# COMPUTE_CLUSTER_ARM_COREPACK_0_COMPUTE_CLUSTER_ARM_COREPACK_0_APBADDR_DBG_CPU0_000730010000h register map
Vendor: Texas Instruments
Registers are 32-bit, read-write, reset 0x0 unless marked. A register's access mark holds for its fields unless they carry their own. Offsets are as the file gives them; [hi:lo] are bit positions; {n}, {i} and the like mark numbered series.

## COMPUTE_CLUSTER_ARM_COREPACK_0_APBADDR_DBG_CPU0 (part 2 of 2)
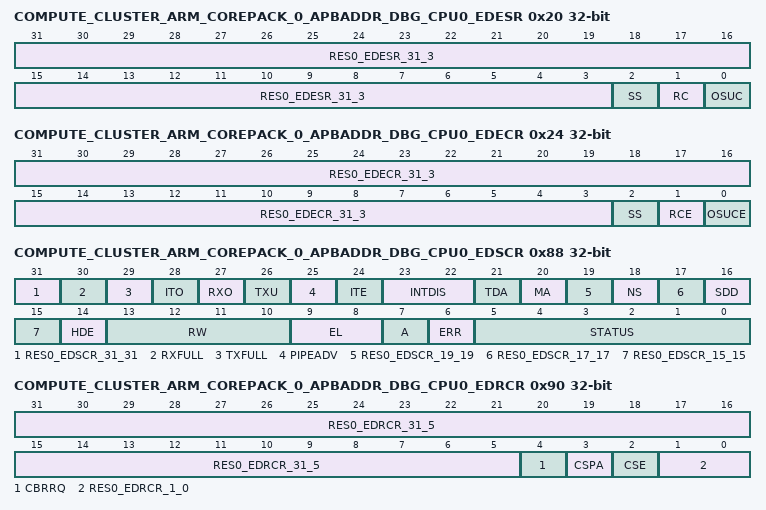
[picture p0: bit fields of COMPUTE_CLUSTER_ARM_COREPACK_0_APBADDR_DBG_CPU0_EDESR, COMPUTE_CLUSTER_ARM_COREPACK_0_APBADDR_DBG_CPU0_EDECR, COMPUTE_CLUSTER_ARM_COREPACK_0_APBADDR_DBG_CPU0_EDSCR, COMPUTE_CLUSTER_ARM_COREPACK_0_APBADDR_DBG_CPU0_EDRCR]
0x20 COMPUTE_CLUSTER_ARM_COREPACK_0_APBADDR_DBG_CPU0_EDESR — External Debug Event Status Register
  [31:3] RES0_EDESR_31_3 — Reserved, RES0.
  [2] SS — Halting step debug event pending. Possible values of this field are: 0 Reading this means that a Halting step debug event is not pending. Writing this means no action. 1 Reading this means that a Halting step debug event is pending. Writing this clears the pending Halting step debug event.
  [1] RC — Reset catch debug event pending. Possible values of this field are: 0 Reading this means that a Reset catch debug event is not pending. Writing this means no action. 1 Reading this means that a Reset catch debug event is pending. Writing this clears the pending Reset catch debug event.
  [0] OSUC — OS unlock debug event pending. Possible values of this field are: 0 Reading this means that an OS unlock catch debug event is not pending. Writing this means no action. 1 Reading this means that an OS unlock catch debug event is pending. Writing this clears the pending OS unlock catch debug event.
0x24 COMPUTE_CLUSTER_ARM_COREPACK_0_APBADDR_DBG_CPU0_EDECR — External Debug Execution Control Register
  [31:3] RES0_EDECR_31_3 — Reserved, RES0.
  [2] SS — Halting step enable. Possible values of this field are: 0 Halting step debug event disabled. 1 Halting step debug event enabled. If the value of EDECR.SS is changed when the processor is in Non-debug state, the resulting value of EDECR.SS is UNKNOWN.
  [1] RCE — Reset catch enable. Possible values of this field are: 0 Reset catch debug event disabled. 1 Reset catch debug event enabled.
  [0] OSUCE — OS unlock catch enabled. Possible values of this field are: 0 OS unlock catch debug event disabled. 1 OS unlock catch debug event enabled.
0x30 COMPUTE_CLUSTER_ARM_COREPACK_0_APBADDR_DBG_CPU0_EDWAR_31_0 — External Debug Watchpoint Address Register (low word)
  [31:0] EDWAR_31_0 — Watchpoint address. The virtual data address being accessed when a watchpoint debug event was triggered and caused entry to Debug state.UNKNOWN if the processor is not in Debug state, or if Debug state was entered other than for a watchpoint debug event.The address must be within a naturally-aligned block of memory of power-of-two size no larger than the DC ZVA block size.
0x34 COMPUTE_CLUSTER_ARM_COREPACK_0_APBADDR_DBG_CPU0_EDWAR_63_32 — External Debug Watchpoint Address Register (high word)
  [31:0] EDWAR_63_32 — Watchpoint address. The virtual data address being accessed when a watchpoint debug event was triggered and caused entry to Debug state.UNKNOWN if the processor is not in Debug state, or if Debug state was entered other than for a watchpoint debug event.The address must be within a naturally-aligned block of memory of power-of-two size no larger than the DC ZVA block size.
0x80 COMPUTE_CLUSTER_ARM_COREPACK_0_APBADDR_DBG_CPU0_DBGDTRRX_EL0 — Debug Data Transfer Register Receive
  [31:0] DBGDTRRX_EL0 — Update DTRRX. Writes to this register update the value in DTRRX and set RXfull to 1.Reads of this register return the last value written to DTRRX and do not change RXfull.
0x84 COMPUTE_CLUSTER_ARM_COREPACK_0_APBADDR_DBG_CPU0_EDITR — External Debug Instruction Transfer Register
  [31:0] EDITR — Used in Debug state for passing instructions to the processor for execution
0x88 COMPUTE_CLUSTER_ARM_COREPACK_0_APBADDR_DBG_CPU0_EDSCR — External Debug Status and Control Register
  [31] RES0_EDSCR_31_31 — Reserved, RES0.
  [30] RXFULL — DTRRX full. This bit is RO.
  [29] TXFULL — DTRTX full. This bit is RO.
  [28] ITO — EDITR overrun. This bit is RO.If the processor is not in Debug state, this bit is UNKNOWN. ITO is set to 0 on entry to Debug state.
  [27] RXO — DTRRX overrun. This bit is RO.
  [26] TXU — DTRTX underrun. This bit is RO.
  [25] PIPEADV — Pipeline advance. Read-only. Set to 1 every time the processor pipeline retires one or more instructions. Cleared to 0 by a write to EDRCR.CSPA.The architecture does not define precisely when this bit is set to 1. It requires only that this happen periodically in Non-debug state to indicate that software execution is progressing.
  [24] ITE — ITR empty. This bit is RO.If the processor is not in Debug state, this bit is UNKNOWN. It is always valid in Debug state.
  [23:22] INTDIS — Interrupt disable. Disables taking interrupts [including virtual interrupts and System Error interrupts] in Non-Debug state.If external invasive debug is disabled, the value of this field is ignored.If external invasive debug is enabled, the possible values of this field are: 00 Do not disable interrupts 01 Disable interrupts targeting Non-secure EL1. 10 Disable interrupts targeting only Non-secure EL1 and Non-secure EL2. If external secure invasive debug is enabled, also disable interrupts targeting Secure EL1. 11 Disable interrupts targeting only Non-secure EL1 and Non-secure EL2. If external secure invasive debug is enabled, also disable all other interrupts. The value of INTdis does not affect whether an interrupt is a WFI wake-up event, but can mask an interrupt as a WFE wake-up event.If EL3 and EL2 are not implemented, INTdis[0] is RO and reads the same value as INTdis[1], meaning only the values 0b00 and 0b11 can be selected.
  [21] TDA — Trap debug registers accesses.
  [20] MA — Memory access mode. Controls use of memory-access mode for accessing EDITR and the DCC. This bit is ignored if in Non-debug state and set to zero on entry to Debug state.Possible values of this field are: 0 Normal access mode 1 Memory access mode.
  [19] RES0_EDSCR_19_19 — Reserved, RES0.
  [18] NS — Non-secure status. Read-only. When in Debug state, gives the current security state: 0 Secure state, IsSecure[] == TRUE 1 Non-secure state, IsSecure[] == FALSE. In Non-debug state, this bit is UNKNOWN.
  [17] RES0_EDSCR_17_17 — Reserved, RES0.
  [16] SDD — Secure debug disabled. This bit is RO.On entry to Debug state:If entering in Secure state, SDD is set to 0.If entering in Non-secure state, SDD is set to the inverse of ExternalSecureInvasiveDebugEnabled[].In Debug state, the value of the SDD bit does not change, even if ExternalSecureInvasiveDebugEnabled[] changes.In Non-debug state:SDD returns the inverse of ExternalSecureInvasiveDebugEnabled[]. If the authentication signals that control ExternalSecureInvasiveDebugEnabled[] change, a context synchronization operation is required to guarantee their effect.This bit is unaffected by the Security state of the processor.If EL3 is not implemented and the implementation is Non-secure, this bit is RES1.
  [15] RES0_EDSCR_15_15 — Reserved, RES0.
  [14] HDE — Halting debug mode enable. Possible values of this bit are: 0 Halting debug mode disabled. 1 Halting debug mode enabled.
  [13:10] RW — Exception level register-width status. Read-only. In Debug state, each bit gives the current register width status of each EL: 1111 All exception levels are AArch64 state. 1110 EL0 is AArch32 state. All other exception levels are AArch64 state. 1100 EL0 and EL1 are AArch32 state. All other exception levels are AArch64 state. Never seen if EL2 is not implemented in the current security state. 1000 EL0, EL1, and, if implemented in the current security state, EL2 are AArch32 state. All other exception levels are AArch64 state. 0000 All exception levels are set to AArch32 state [32-bit configuration]. However:If not at EL0: RW[0] == RW[1].If EL2 is not implemented in the current security state: RW[2] == RW[1].If EL3 is not implemented: RW[3] == RW[2].In Non-debug state, this field is RAO.
  [9:8] EL — Exception level. Read-only. In Debug state, this gives the current EL of the processor.In Non-debug state, this field is RAZ.
  [7] A — System Error interrupt pending. Read-only. In Debug state, indicates whether a SError interrupt is pending:If HCR_EL2.{AMO, TGE} = {1, 0} and in Non-secure EL0 or EL1, a virtual SError interrupt.Otherwise, a physical SError interrupt. 0 No SError interrupt pending. 1 SError interrupt pending. A debugger can read EDSCR to check whether a SError interrupt is pending without having to execute further instructions. A pending SError might indicate data from target memory is corrupted.UNKNOWN in Non-debug state.
  [6] ERR — Cumulative error flag. This field is RO. It is set to 1 following exceptions in Debug state and on any signaled overrun or underrun on the DTR or EDITR.
  [5:0] STATUS — Debug status flags. This field is RO.The possible values of this field are: 000010 Processor is in Non-debug state. 000001 Processor is restarting [exiting Debug state]. 000111 Breakpoint. 010011 External debug request. 011011 Halting step, normal. 011111 Halting step, exclusive. 100011 OS unlock catch. 100111 Reset catch. 101011 Watchpoint. 101111 HLT instruction. 110011 Software access to debug register. 110111 Exception catch. 111011 Halting step, no syndrome. All other values of STATUS are reserved.
0x8C COMPUTE_CLUSTER_ARM_COREPACK_0_APBADDR_DBG_CPU0_DBGDTRTX_EL0 — Debug Data Transfer Register Transmit
  [31:0] DBGDTRTX_EL0 — Return DTRTX. Reads of this register return the value in DTRTX and clear TXfull to 0.Writes of this register update the value in DTRTX and do not change TXfull.
0x90 COMPUTE_CLUSTER_ARM_COREPACK_0_APBADDR_DBG_CPU0_EDRCR — External Debug Reserve Control Register
  [31:5] RES0_EDRCR_31_5 — Reserved, RES0.
  [4] CBRRQ — Allow imprecise entry to Debug state. The actions on Writing to this bit are: 0 No action. 1 Allow imprecise entry to Debug state, for example by canceling pending bus accesses. Setting this bit to 1 allows a debugger to request imprecise entry to Debug state. An External Debug Request debug event must be pending before the debugger sets this bit to 1.This feature is optional. If this feature is not implemented, writes to this bit are ignored.
  [3] CSPA — Clear Sticky Pipeline Advance. This bit is used to clear the EDSCR.PipeAdv bit to 0. The actions on Writing to this bit are: 0 No action. 1 Clear the EDSCR.PipeAdv bit to 0.
  [2] CSE — Clear Sticky Error. Used to clear the EDSCR cumulative error bits to 0. The actions on Writing to this bit are: 0 No action. 1 Clear the EDSCR.{TXU, RXO, ERR} bits, and, if the processor is in Debug state, the EDSCR.ITO bit, to 0.
  [1:0] RES0_EDRCR_1_0 — Reserved, RES0.
0x94 COMPUTE_CLUSTER_ARM_COREPACK_0_APBADDR_DBG_CPU0_EDACR — External Debug Auxiliary Control Register
  [31:0] RES0_EDACR_31_0 — Reserved RES0
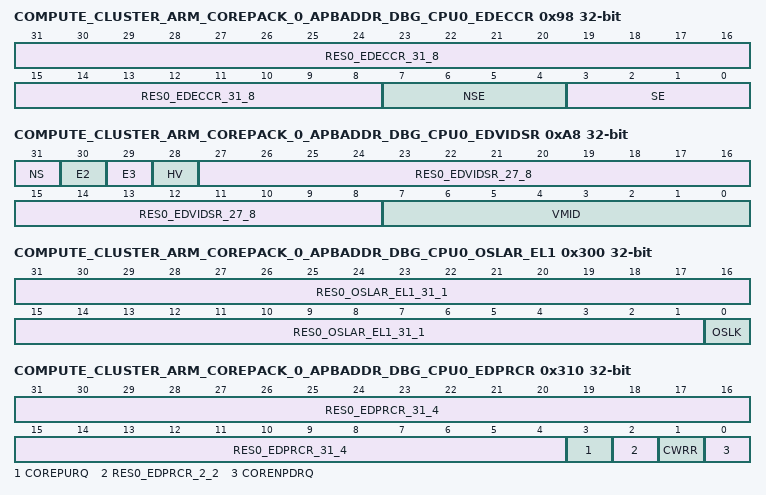
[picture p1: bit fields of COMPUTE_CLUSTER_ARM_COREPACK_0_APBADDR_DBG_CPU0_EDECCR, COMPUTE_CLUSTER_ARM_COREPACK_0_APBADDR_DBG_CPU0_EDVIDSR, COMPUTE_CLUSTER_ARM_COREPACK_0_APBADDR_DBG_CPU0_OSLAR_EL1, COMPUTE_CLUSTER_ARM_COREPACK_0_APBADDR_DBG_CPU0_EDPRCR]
0x98 COMPUTE_CLUSTER_ARM_COREPACK_0_APBADDR_DBG_CPU0_EDECCR — External Debug Exception Catch Control Register
  [31:8] RES0_EDECCR_31_8 — Reserved, RES0.
  [7:4] NSE — Coarse-grained Non-secure exception catch. Possible values of this field are: 0000 Exception catch debug event disabled for Non-secure exception levels. 0010 Exception catch debug event enabled for Non-secure EL1. 0100 Exception catch debug event enabled for Non-secure EL2. 0110 Exception catch debug event enabled for Non-secure EL1 and EL2. All other values are reserved. Bits [7,4] are reserved, RES0.
  [3:0] SE — Coarse-grained Secure exception catch. Possible values of this field are: 0000 Exception catch debug event disabled for Secure exception levels. 0010 Exception catch debug event enabled for Secure EL1. 1000 Exception catch debug event enabled for Secure EL3. 1010 Exception catch debug event enabled for Secure EL1 and EL3. All other values are reserved. Bits [2,0] are reserved. RES0. Ignored if ExternalSecureInvasiveDebugEnabled[] == FALSE.
0xA0 COMPUTE_CLUSTER_ARM_COREPACK_0_APBADDR_DBG_CPU0_EDPCSR_31_0 — External Debug Program Counter Sample Register (low word)
  [31:0] EDPCSR_31_0 — PC Sample low word, EDPCSRlo. Bits [31_0] of the sampled instruction address value. Reading EDPCSRlo has the side-effect of updating EDCIDSR, EDVIDSR, and EDPCSRhi. However:If the processor is in Debug state, or Sample-based profiling is prohibited, EDPCSRlo reads as 0xFFFFFFFF and EDCIDSR, EDVIDSR, and EDPCSRhi become UNKNOWN.If the processor is in Reset state, the sampled value is unknown and EDCIDSR, EDVIDSR and EDPCSRhi become UNKNOWN.If no instruction has been retired since the processor left Reset state, Debug state, or a state where Non-invasive debug is not permitted, the sampled value is UNKNOWN and EDCIDSR, EDVIDSR, and EDPCSRhi become UNKNOWN.For a read of EDPCSRlo from the memory-mapped interface, if EDLSR.SLK == 1, meaning the Software Lock is locked, then the access has no side-effects. That is, EDCIDSR, EDVIDSR, and EDPCSRhi are unchanged.
0xA4 COMPUTE_CLUSTER_ARM_COREPACK_0_APBADDR_DBG_CPU0_EDCIDSR — External Debug Context ID Sample Register
  [31:0] CONTEXTIDR — The sampled value of CONTEXTIDR_EL1, captured on Reading the low half of EDPCSR.If EL3 is implemented and using AArch32 then CONTEXTIDR is a Banked register, and EDCIDSR samples the current Banked copy of CONTEXTIDR.
0xA8 COMPUTE_CLUSTER_ARM_COREPACK_0_APBADDR_DBG_CPU0_EDVIDSR — External Debug Virtual Context Sample Register
  [31] NS — Non-secure state sample. Indicates the security state associated with the most recent EDPCSR sample.
  [30] E2 — Exception level 2 status sample. Indicates whether the most recent EDPCSR sample was associated with EL2. If EDVIDSR.NS == 0, this bit is 0.
  [29] E3 — Exception level 3 status sample. Indicates whether the most recent EDPCSR sample was associated with AArch64 EL3. If EDVIDSR.NS == 1 or the processor was in AArch32 state when EDPCSR was read, this bit is 0.
  [28] HV — EDPCSR high half valid. Indicates whether bits [63_32] of the most recent EDPCSR sample are valid. If EDVIDSR.HV == 0, the value of EDPCSR[63_32] is RAZ.
  [27:8] RES0_EDVIDSR_27_8 — Reserved, RES0.
  [7:0] VMID — VMID sample. The value of VTTBR_EL2.VMID associated with the most recent EDPCSR sample. If EDVIDSR.NS == 0 or EDVIDSR.E2 == 1, this field is RAZ.
0xAC COMPUTE_CLUSTER_ARM_COREPACK_0_APBADDR_DBG_CPU0_EDPCSR_63_32 — External Debug Program Counter Sample Register (high word)
  [31:0] EDPCSR_63_32 — PC Sample high word, EDPCSRhi. If EDVIDSR.HV == 0 then this field is RAZ, otherwise bits [63_32] of the sampled PC.
0x300 COMPUTE_CLUSTER_ARM_COREPACK_0_APBADDR_DBG_CPU0_OSLAR_EL1 — OS Lock Access Register
  [31:1] RES0_OSLAR_EL1_31_1 — Reserved, RES0.
  [0] OSLK — On writes to OSLAR_EL1, bit[0] is copied to the OS lock.Use EDPRSR.OSLK to check the current status of the lock.
0x310 COMPUTE_CLUSTER_ARM_COREPACK_0_APBADDR_DBG_CPU0_EDPRCR — External Debug Power/Reset Control Register
  [31:4] RES0_EDPRCR_31_4 — Reserved, RES0.
  [3] COREPURQ — Core powerup request. Allows a debugger to request that the power controller power up the core, enabling access to the debug register in the Core power domain. The actions on Writing to this bit are: 0 No effect. 1 Request the power controller to powerup the core. In an implementation that includes the recommended external debug interface, this bit drives the DBGPWRUPREQ signal.This bit can be read and written when the Core power domain is powered off.The power controller must not allow the Core power domain to switch off while this bit is one.
  [2] RES0_EDPRCR_2_2 — Reserved, RES0.
  [1] CWRR — Warm reset request. Write only bit that reads as zero. The actions on Writing to this bit are: 0 No action. 1 Request Warm reset. The processor ignores writes to this bit if any of the following are the case:ExternalInvasiveDebugEnabled[] == FALSE, EL3 is not implemented, and the processor is Non-secure.ExternalSecureInvasiveDebugEnabled[] == FALSE and one of the following is true:EL3 is implemented.The processor is Secure.The Core power domain is either completely off or in a low-power state where the Core power domain registers cannot be accessed.DoubleLockStatus[] == TRUE [OS Double Lock is set].OSLSR.OSLK == 1 [OS lock is locked].In an implementation that includes the recommended external debug interface, this bit drives the DBGRSTREQ signal.
  [0] CORENPDRQ — Core no powerdown request. Requests emulation of powerdown. Possible values of this bit are: 0 On a powerdown request, the system powers down the Core power domain. 1 On a powerdown request, the system emulates powerdown of the Core power domain. In this emulation mode the Core power domain is not actually powered down.
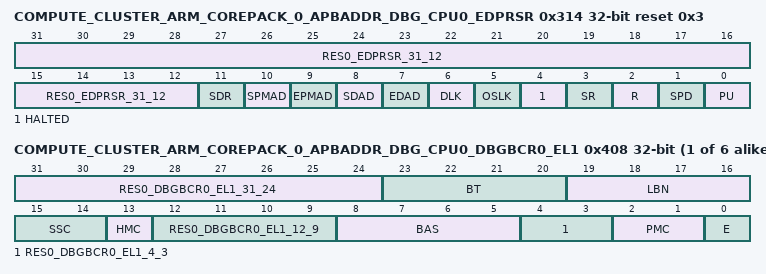
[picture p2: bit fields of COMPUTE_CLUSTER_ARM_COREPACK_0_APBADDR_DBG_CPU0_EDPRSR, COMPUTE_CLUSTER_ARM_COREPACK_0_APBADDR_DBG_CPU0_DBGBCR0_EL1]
0x314 COMPUTE_CLUSTER_ARM_COREPACK_0_APBADDR_DBG_CPU0_EDPRSR reset 0x3 — External Debug Processor Status Register
  [31:12] RES0_EDPRSR_31_12 — Reserved, RES0.
  [11] SDR — Sticky debug restart. Set to 1 when the processor exits Debug state and cleared to 0 following reads of EDPRSR. 0 The processor has not restarted since EDPRSR was last read. 1 The processor has restarted since EDPRSR was last read. This bit is UNKNOWN on reads if either of EDPRSR.{DLK, R} is 1, or EDPRSR.PU is 0.This bit clears to 0 when following a read of EDPRSR.
  [10] SPMAD — Sticky EPMAD error. Set to 1 if an access returns an error because AllowExternalPMUAccess[] == FALSE. 0 No accesses to the external performance monitors registers have failed since EDPRSR was last read. 1 At least one access to the external performance monitors registers has failed since EDPRSR was last read. This bit is UNKNOWN on reads if either of EDPRSR.{DLK, R} is 1, or EDPRSR.PU is 0.This bit clears to 0 when following a read of EDPRSR.
  [9] EPMAD — External performance monitors access disable status. 0 External performance monitors access enabled. 1 External performance monitors access disabled. If external performance monitors access is not implemented, EPMAD is RAO. This bit is UNKNOWN on reads if either of EDPRSR.{DLK, R} is 1, or EDPRSR.PU is 0.
  [8] SDAD — Sticky EDAD error. Set to 1 if an access returns an error because AllowExternalDebugAccess[] == FALSE. 0 No accesses to the external debug registers have failed since EDPRSR was last read. 1 At least one access to the external debug registers has failed since EDPRSR was last read. This bit is UNKNOWN on reads if either of EDPRSR.{DLK, R} is 1, or EDPRSR.PU is 0.This bit clears to 0 following a read of EDPRSR.
  [7] EDAD — External debug access disable status. 0 External debug access enabled. 1 External debug access disabled. This bit is UNKNOWN on reads if either of EDPRSR.{DLK, R} is 1, or EDPRSR.PU is 0.
  [6] DLK — OS Double Lock status bit. 0 OSDLR_EL1.DLK == 0 or EDPRCR.CORENPDRQ == 1 or the processor is in Debug state. 1 OSDLR_EL1.DLK == 1 and EDPRCR.CORENPDRQ == 0 and the processor is in Non-debug state. This bit is UNKNOWN on reads if EDPRSR.PU is 0.
  [5] OSLK — OS lock status bit. A read of this bit returns the value of OSLSR_EL1.OSLK.This bit is UNKNOWN on reads if either of EDPRSR.{DLK, R} is 1 or EDPRSR.PU is 0.
  [4] HALTED — Halted status bit. Possible values are: 0 EDSCR.STATUS is 0b000010 [processor in Non-debug state]. 1 EDSCR.STATUS is not 0b000010. This bit is UNKNOWN on reads if EDPRSR.PU is 0.
  [3] SR — Sticky core reset status bit. Possible values are: 0 The non-debug logic of the processor is not in reset state and has not been reset since the last time EDPRSR was read. 1 The non-debug logic of the processor is in reset state or has been reset since the last time EDPRSR was read. This bit is UNKNOWN on reads if EDPRSR.DLK is 1 or EDPRSR.PU is 0.This bit clears to 0 following a read of EDPRSR if the non-debug logic of the processor is not in reset state.
  [2] R — Core reset status bit. Possible values are: 0 The non-debug logic of the processor is not in reset state. 1 The non-debug logic of the processor is in reset state. This bit is UNKNOWN on reads if either EDPRSR.DLK is 1 or EDPRSR.PU is 0.
  [1] SPD — Sticky core power-down status bit.This bit is set to 1 on Cold reset to indicate the state of the debug registers has been lost. Since a Cold reset is required on powering up the processor, this usually indicates the Core power domain has been completely powered off.Possible values are: 0 If the Core power domain is off [EDPRSR.PU is 0], it is not known whether the state of the debug registers in the Core power domain is lost. Otherwise, the Core power domain is on, and the state of the debug registers in the Core power domain has not been lost. 1 The state of the debug registers in the Core power domain is lost. This bit is UNKNOWN on reads if both EDPRSR.DLK and EDPRSR.PU are 1.This bit clears to 0 following a read of EDPRSR if the processor is not in the powered down state. There are two logical power off states for the Core power domain:RetentionThe states of the debug registers, including EDPRSR.SPD, in the Core power domain is preserved, and restored on leaving retention state.Power-downThe states of the debug registers in the Core power domain is lost, and a Cold reset is asserted on leaving power-down state.In these states, it is IMPLEMENTATION DEFINED whether:EDPRSR.SPD shows whether the state of the debug registers in the Core power domain has been lost since the last time EDPRSR was read when the Core power domain was on.EDPRSR.SPD reads-as-zero.EDPRSR.SPD is not cleared following a read of EDPRSR in these states.This means it is IMPLEMENTATION DEFINED whether a processor implements EDPRSR.SPD as:Fixed RAZ when in one or both of the retention and power-down states.Retaining its previous value when in the retention state.Fixed RAO in the power-down state.Note that this definition does not allow EDPRSR.SPD to be fixed RAO in the low-power retention state, as the state of the debug registers in the Core power domain is not lost by entering this state. However, the bit can be read as 1 in this state if the state of the registers was lost before entering this state [i.e. EDPRSR has not been read since the last Cold reset].ARM recommends that an implementation make EDPRSR.SPD fixed RAO when in the power-down state, particularly if it does not support a low-power retention state.
  [0] PU — Core power-up status bit. Indicates whether the Core power domain debug registers can be accessed: 0 Core is in a low-power or power-down state where the debug registers cannot be accessed. 1 Core is in a power-up state where the debug registers can be accessed.
{0x400+0x10*i} COMPUTE_CLUSTER_ARM_COREPACK_0_APBADDR_DBG_CPU0_DBGBVR{i}_EL1_31_0 (i=0..5) — Debug Breakpoint Value Registers. Holds a virtual address or a VMID and/or a context ID for use in breakpoint matching. Forms breakpoint n together with control register DBGBCR{i}_EL1. Multiple uses of this register refer to ARMv8
  [31:0] DBGBVR{i}_EL1_31_0 — Holds a virtual address or a VMID and/or a context ID for use in breakpoint matching
{0x404+0x10*i} COMPUTE_CLUSTER_ARM_COREPACK_0_APBADDR_DBG_CPU0_DBGBVR{i}_EL1_63_32 (i=0..5) — Debug Breakpoint Extended Value Registers. Holds a virtual address or a VMID and/or a context ID for use in breakpoint matching. Forms breakpoint n together with control register DBGBCR{i}_EL1. Multiple uses of this register refer to ARMv8
  [31:0] DBGBVR{i}_EL1_63_32 — Holds a virtual address or a VMID and/or a context ID for use in breakpoint matching
{0x408+0x10*i} COMPUTE_CLUSTER_ARM_COREPACK_0_APBADDR_DBG_CPU0_DBGBCR{i}_EL1 (i=0..5) — Debug Breakpoint Control Register {i}
  [31:24] RES0_DBGBCR{i}_EL1_31_24 — Reserved, RES0.
  [23:20] BT — Breakpoint Type. Possible values are: 0000 Unlinked instruction address match. 0001 Linked instruction address match. 0010 Unlinked context ID match. 0011 Linked context ID match 0100 Unlinked instruction address mismatch. 0101 Linked instruction address mismatch. 1000 Unlinked VMID match. 1001 Linked VMID match. 1010 Unlinked VMID and context ID match. 1011 Linked VMID and context ID match. The field breaks down as follows:BT[3:1]: Base type.000Match address. DBGBVR<n>_EL1 is the address of an instruction.010Mismatch address. Behaves as type 0b000 if in an AArch64 translation, or if halting debug-mode is enabled and halting is allowed. Otherwise, DBGBVR<n>_EL1 is the address of an instruction to be stepped.001Match context ID. DBGBVR<n>_EL1[31_0] is a context ID.100Match VMID. DBGBVR<n>_EL1[39:32] is a VMID.101Match VMID and context ID. DBGBVR<n>_EL1[31_0] is a context ID, and DBGBVR<n>_EL1[39:32] is a VMID.BT[0]: Enable linking.If the breakpoint is not context-aware, BT[3] and BT[1] are RES0. If EL2 is not implemented, BT[3] is RES0. If EL1 using AArch32 is not implemented, BT[2] is RES0.The values 011x and 11xx are reserved, but must behave as if the breakpoint is disabled. Software must not rely on this property as the behavior of reserved values might change in a future revision of the architecture.
  [19:16] LBN — Linked breakpoint number. For Linked address matching breakpoints, this specifies the index of the Context-matching breakpoint linked to.
  [15:14] SSC — Security state control. Determines the security states under which a breakpoint debug event for breakpoint n is generated. This field must be interpreted along with the HMC and PMC fields.
  [13] HMC — Higher mode control. Determines the debug perspective for deciding when a breakpoint debug event for breakpoint n is generated. This field must be interpreted along with the SSC and PMC fields.
  [12:9] RES0_DBGBCR{i}_EL1_12_9 — Reserved, RES0.
  [8:5] BAS — Byte address select. Defines which half-words an address-matching breakpoint matches, regardless of the instruction set and execution state. In an AArch64-only implementation, this field is reserved, RES1. Otherwise:BAS[2] and BAS[0] are read/write.BAS[3] and BAS[1] are read-only copies of BAS[2] and BAS[0] respectively.The values 0b0011 and 0b1100 are only supported if AArch32 is supported at any exception level.The permitted values depend on the breakpoint type.For Address match breakpoints in either AArch32 or AArch64 state:BASMatch instruction atConstraint for debuggers0b0011DBGBVR<n>_EL1Use for T32 and T32EE instructions.0b1100DBGBVR<n>_EL1+2Use for T32 and T32EE instructions.0b1111DBGBVR<n>_EL1Use for A64 and A32 instructions.0b0000 is reserved and must behave as if the breakpoint is disabled or map to a permitted value.For Address mismatch breakpoints in an AArch32 stage 1 translation regime:BASStep instruction atConstraint for debuggers0b0000-Use for a match anywhere breakpoint.0b0011DBGBVR<n>_EL1Use for stepping T32 and T32EE instructions.0b1100DBGBVR<n>_EL1+2Use for stepping T32 and T32EE instructions.0b1111DBGBVR<n>_EL1Use for stepping A64 and A32 instructions.For Context matching breakpoints, this field is RES1 and ignored.
  [4:3] RES0_DBGBCR{i}_EL1_4_3 — Reserved, RES0.
  [2:1] PMC — Privilege mode control. Determines the exception level or levels at which a breakpoint debug event for breakpoint n is generated. This field must be interpreted along with the SSC and HMC fields.
  [0] E — Enable breakpoint DBGBVR<n>_EL1. Possible values are: 0 Breakpoint disabled. 1 Breakpoint enabled.
